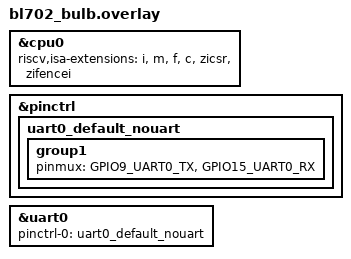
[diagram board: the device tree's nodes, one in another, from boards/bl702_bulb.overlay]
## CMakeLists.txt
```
cmake_minimum_required(VERSION 3.20.0)

find_package(Zephyr REQUIRED HINTS $ENV{ZEPHYR_BASE})

project(bl702_bulb)

get_filename_component(CHIP_ROOT ${ZEPHYR_BASE}/../modules/lib/matter REALPATH)

include(${CHIP_ROOT}/src/app/chip_data_model.cmake)

target_include_directories(app PRIVATE
    include
    ${CHIP_ROOT}/zzz_generated/app-common)

target_sources(app PRIVATE
    src/main.cpp
    src/ZclCallbacks.cpp
    src/LightDriver.cpp
    src/atomic_helpers.c)

# Generates and compiles the endpoint/cluster code
chip_configure_data_model(app ZAP_FILE ${CMAKE_CURRENT_SOURCE_DIR}/lighting-app.zap)

if(NOT DEFINED ZEPHYR_CONNECTEDHOMEIP_MODULE_DIR)
    message(FATAL_ERROR "Matter is not registered as a Zephyr module. Add it to your west manifest.")
endif()
set(CHIP_ROOT ${ZEPHYR_CONNECTEDHOMEIP_MODULE_DIR})

# ot-config re-lists zephyr_interface's INTERFACE_COMPILE_DEFINITIONS, including
# $<COMPILE_LANGUAGE:CXX> generator expressions. openthread/CMakeLists.txt uses
# ot-config's defines to build a plain custom target, where COMPILE_LANGUAGE is
# invalid. Strip it so LLVM/Clang builds configure cleanly.
if(CONFIG_OPENTHREAD AND TARGET ot-config AND TARGET zephyr_interface)
    get_target_property(OT_CONFIG_DEFS ot-config INTERFACE_COMPILE_DEFINITIONS)
    if(OT_CONFIG_DEFS)
        list(FILTER OT_CONFIG_DEFS EXCLUDE REGEX "TARGET_PROPERTY:zephyr_interface,INTERFACE_COMPILE_DEFINITIONS")
    else()
        set(OT_CONFIG_DEFS "")
    endif()
    get_target_property(ZEPHYR_INTERFACE_DEFS zephyr_interface INTERFACE_COMPILE_DEFINITIONS)
    if(ZEPHYR_INTERFACE_DEFS)
        list(FILTER ZEPHYR_INTERFACE_DEFS EXCLUDE REGEX "COMPILE_LANGUAGE:CXX")
    else()
        set(ZEPHYR_INTERFACE_DEFS "")
    endif()
    set_target_properties(ot-config PROPERTIES
        INTERFACE_COMPILE_DEFINITIONS "${OT_CONFIG_DEFS};${ZEPHYR_INTERFACE_DEFS}")
endif()

include(${CHIP_ROOT}/src/app/chip_data_model.cmake)

target_compile_options(app PRIVATE -Werror -Wno-error=format)
if(CMAKE_C_COMPILER_ID STREQUAL "GNU")
    target_compile_options(app PRIVATE -Werror -Wno-error=maybe-uninitialized)
endif()

if(NOT APP_TASK_IMPL_HEADER STREQUAL "")
    target_compile_definitions(app PRIVATE APP_TASK_IMPL_HEADER="${APP_TASK_IMPL_HEADER}")
endif()

zephyr_linker_sources(RAM_SECTIONS reloc.ld)
zephyr_code_relocate(FILES
  ${ZEPHYR_BASE}/subsys/net/ip/net_if.c
  ${ZEPHYR_BASE}/subsys/net/ip/connection.c
  ${ZEPHYR_BASE}/subsys/net/ip/net_context.c
  ${ZEPHYR_BASE}/modules/mbedtls/zephyr_init.c
  ${ZEPHYR_BASE}/subsys/settings/src/settings_nvs.c
  LOCATION RETRAM_BSS)
zephyr_code_relocate(FILES
  src/main.cpp
  LOCATION ITCM_BSS)
```

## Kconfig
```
menu "Zephyr"
source "Kconfig.zephyr"
endmenu

module = APP
module-str = APP
source "subsys/logging/Kconfig.template.log_config"

if NET_L2_OPENTHREAD
choice OPENTHREAD_DEVICE_TYPE
	default OPENTHREAD_FTD
endchoice
endif # NET_L2_OPENTHREAD
```

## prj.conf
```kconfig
# A lot of this is the *absolute minimum* possible to use matter, it was never intended to run
# on a device with that little RAM

CONFIG_NETWORKING=y
CONFIG_NET_L2_OPENTHREAD=y
CONFIG_OPENTHREAD_THREAD_VERSION_1_2=y
CONFIG_OPENTHREAD_SLAAC=y
CONFIG_OPENTHREAD_MANUAL_START=y
CONFIG_OPENTHREAD_DEFAULT_TX_POWER=13

# Logging
CONFIG_LOG=n
# CONFIG_LOG_MAX_LEVEL=3
# CONFIG_MATTER_LOG_LEVEL=1
# CONFIG_LOG_MODE_MINIMAL=y

# Use NVS as settings backend
CONFIG_NVS=y
CONFIG_NVS_LOOKUP_CACHE=y
CONFIG_NVS_LOOKUP_CACHE_SIZE=128
CONFIG_NVS_INIT_BAD_MEMORY_REGION=y

# Kernel options
CONFIG_MAIN_STACK_SIZE=4096
CONFIG_INIT_STACKS=y

# Control
CONFIG_LED=y
CONFIG_LED_PWM=y

# Safety
CONFIG_WATCHDOG=y
CONFIG_REBOOT=y

# BLE for provisioning
CONFIG_BT=y
CONFIG_BT_PERIPHERAL=y
CONFIG_BT_DEVICE_NAME="BL702 Bulb"
CONFIG_BT_GAP_AUTO_UPDATE_CONN_PARAMS=y
CONFIG_BT_GATT_DYNAMIC_DB=y
CONFIG_BT_DEVICE_NAME_DYNAMIC=y
CONFIG_BT_DEVICE_NAME_GATT_WRITABLE=n
CONFIG_BT_BUF_ACL_TX_COUNT=2
CONFIG_BT_BUF_EVT_RX_COUNT=4
CONFIG_BT_BUF_ACL_RX_SIZE=100
CONFIG_BT_BUF_ACL_TX_SIZE=100
CONFIG_BT_L2CAP_TX_MTU=100

# Matter
CONFIG_CHIP=y
CONFIG_CHIP_PROJECT_CONFIG="include/CHIPProjectConfig.h"
CONFIG_CHIP_DEVICE_PRODUCT_ID=32773
CONFIG_CHIP_ENABLE_PAIRING_AUTOSTART=y
CONFIG_CHIP_FACTORY_DATA=n
CONFIG_CHIP_CRYPTO_PSA=y
CONFIG_CHIP_BLE_ADVERTISING_DURATION=15
CONFIG_CHIP_MALLOC_SYS_HEAP=y
CONFIG_CHIP_DEVICE_PRODUCT_NAME="BL702 Bulb"
CONFIG_CHIP_DEVICE_VENDOR_NAME="Zephyr Community"
# It is a RGBW dimmable Lamp with 5 PWM channels
CONFIG_CHIP_DEVICE_TYPE=269
CONFIG_CHIP_DEVICE_SOFTWARE_VERSION_STRING="Yes, there is software"
CONFIG_CHIP_DEVICE_HARDWARE_VERSION_STRING="Yes, there is hardware"
CONFIG_CHIP_DEVICE_SOFTWARE_VERSION=1
CONFIG_CHIP_DEVICE_HARDWARE_VERSION=1
CONFIG_CHIP_EXAMPLE_DEVICE_INFO_PROVIDER=n

CONFIG_POSIX_AEP_CHOICE_NONE=y

# Don't starve BLE by starting thread after a factory reset
CONFIG_CHIP_FACTORY_RESET_ERASE_SETTINGS=y

CONFIG_NET_IF_MCAST_IPV6_ADDR_COUNT=8
CONFIG_NET_IF_UNICAST_IPV6_ADDR_COUNT=6
CONFIG_NET_PKT_RX_COUNT=6
CONFIG_NET_PKT_TX_COUNT=4
CONFIG_NET_BUF_RX_COUNT=16
CONFIG_NET_BUF_TX_COUNT=12

CONFIG_STD_CPP17=y
CONFIG_BT_HOST_CRYPTO=y
CONFIG_SYSTEM_WORKQUEUE_STACK_SIZE=1024
CONFIG_MAIN_STACK_SIZE=2944
# CONFIG_SHELL_STACK_SIZE=3072
CONFIG_OPENTHREAD_THREAD_STACK_SIZE=5120

CONFIG_THREAD_LOCAL_STORAGE=y
# CONFIG_ASSERT=y

CONFIG_SHELL=n
#CONFIG_SHELL_MINIMAL=y
CONFIG_CHIP_LIB_SHELL=n
CONFIG_OPENTHREAD_SHELL=n

CONFIG_MBEDTLS_PSA_KEY_SLOT_COUNT=32
CONFIG_MBEDTLS_ENTROPY_C=y
CONFIG_MBEDTLS_PSA_DRIVER_GET_ENTROPY=y
CONFIG_MBEDTLS_PSA_STATIC_KEY_SLOTS=n
CONFIG_MBEDTLS_SSL_IN_CONTENT_LEN=1560
CONFIG_MBEDTLS_SSL_OUT_CONTENT_LEN=1560
CONFIG_MBEDTLS_ENABLE_HEAP=n

# CONFIG_COMMON_LIBC_MALLOC=y
# CONFIG_COMMON_LIBC_MALLOC_ARENA_SIZE=16384

# Save ram
CONFIG_CHIP_OPENTHREAD_FTD=n
CONFIG_OPENTHREAD_MTD=y
CONFIG_CHIP_ENABLE_DNS_CLIENT=n
CONFIG_OPENTHREAD_DNS_CLIENT=n
CONFIG_OPENTHREAD_NUM_MESSAGE_BUFFERS=48
CONFIG_OPENTHREAD_MAX_CHILDREN=1
CONFIG_OPENTHREAD_MAX_IP_ADDR_PER_CHILD=4
CONFIG_OPENTHREAD_TMF_ADDRESS_CACHE_ENTRIES=0
CONFIG_MAX_EVENT_QUEUE_SIZE=40
CONFIG_BT_GATT_CACHING=n
CONFIG_BT_LONG_WQ=n
CONFIG_POSIX_THREAD_THREADS_MAX=1
CONFIG_MAX_PTHREAD_MUTEX_COUNT=1
CONFIG_MAX_PTHREAD_COND_COUNT=1
CONFIG_MAX_PTHREAD_BARRIER_COUNT=1
CONFIG_NET_TC_RX_COUNT=0

CONFIG_NET_IPV6_NBR_CACHE=n
CONFIG_NET_IPV6_ND=n
CONFIG_NET_IPV6_DAD=n
CONFIG_NET_IPV6_MLD=n

CONFIG_BFLB_SHIM_HEAP_SIZE=4096
CONFIG_HEAP_MEM_POOL_SIZE=6144
CONFIG_HEAP_MEM_POOL_IGNORE_MIN=y
CONFIG_CBPRINTF_FP_SUPPORT=n
CONFIG_PICOLIBC_IO_FLOAT=n

# Slightly dangerous but only a possible (rare) problem for setup
CONFIG_BT_TX_PROCESSOR_THREAD=n

CONFIG_IDLE_STACK_SIZE=320
```

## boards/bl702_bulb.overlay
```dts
// /delete-node/ &slot0_partition;
// /delete-node/ &storage_partition;
//
// &kh25v80 {
// 	partitions {
// 		ranges;
// 		#address-cells = <1>;
// 		#size-cells = <1>;
//
// 		slot0_partition: partition@2000 {
// 			compatible = "zephyr,mapped-partition";
// 			label = "image-0";
// 			reg = <0x00002000 (0x00200000 - 0x2000)>;
// 			read-only;
// 		};
//
// 		storage_partition: partition@200000 {
// 			compatible = "zephyr,mapped-partition";
// 			label = "storage";
// 			reg = <0x00200000 0x200000>;
// 		};
// 	};
// };
//
// &sram0_bt {
// 	reg = <0x0 DT_SIZE_K(128)>;
// 	ranges = <0x0 0x0 DT_SIZE_K(128)>;
// };

/* Remove A extension */
&cpu0 {
	riscv,isa-extensions = "i", "m", "f", "c", "zicsr", "zifencei";
};


&pinctrl {
	uart0_default_nouart: uart0_default_nouart {
		group1 {
			pinmux = <GPIO9_UART0_TX>,
				 <GPIO15_UART0_RX>;
		};
	};
};

&uart0 {
	pinctrl-0 = <&uart0_default_nouart>;
	pinctrl-names = "default";
};
```

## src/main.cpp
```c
/*
 * Copyright (c) 2022-2026 Project CHIP Authors
 *
 * SPDX-License-Identifier: Apache-2.0
 *
 * Adapted from examples/platform/telink/common/src/mainCommon.cpp and
 * AppTaskCommon.cpp. Removed: buttons, LEDs, PWM manager, factory data, OTA,
 * identify effects, power-on factory reset, the application thread.
 *
 */

#include "LightDriver.h"

#include <string.h>

#include <zephyr/kernel.h>
#include <zephyr/logging/log.h>
#include <zephyr/bluetooth/bluetooth.h>
#include <zephyr/drivers/watchdog.h>
#include <zephyr/drivers/hwinfo.h>
#include <zephyr/settings/settings.h>
#include <zephyr/sys/util.h>
#include <zephyr/sys/reboot.h>

#include <app-common/zap-generated/attributes/Accessors.h>
#include <app/clusters/network-commissioning/network-commissioning.h>
#include <app/server/Server.h>
#include <credentials/DeviceAttestationCredsProvider.h>
#include <credentials/examples/DeviceAttestationCredsExample.h>
#include <data-model-providers/codegen/Instance.h>
#include <lib/support/CHIPMem.h>
#include <platform/CHIPDeviceLayer.h>
#include <platform/OpenThread/GenericNetworkCommissioningThreadDriver.h>
#include <setup_payload/OnboardingCodesUtil.h>

#ifdef CONFIG_WATCHDOG
#define WDT_TIMEOUT_MS     10000
#define WDT_FEED_PERIOD_MS 1000
static const struct device *const wdt = DEVICE_DT_GET(DT_ALIAS(watchdog0));
#endif

#define STEP_MS		72
#define STEP_CNT	24
#define BR_SCALE(v)	(v / 4U)

LOG_MODULE_REGISTER(app, CONFIG_CHIP_APP_LOG_LEVEL);

/* Commission indicating */
static bool attached = false;
static bool commissioned = false;
static bool started = false;
static size_t step = 0;
const uint8_t pwm_curve[STEP_CNT] = {
	BR_SCALE(0), BR_SCALE(17), BR_SCALE(32), BR_SCALE(45), BR_SCALE(57),  BR_SCALE(68), BR_SCALE(77), BR_SCALE(85), BR_SCALE(91), BR_SCALE(95), BR_SCALE(98), BR_SCALE(100),
	BR_SCALE(100), BR_SCALE(98), BR_SCALE(95), BR_SCALE(91), BR_SCALE(85), BR_SCALE(77), BR_SCALE(68), BR_SCALE(57), BR_SCALE(45), BR_SCALE(32), BR_SCALE(17), BR_SCALE(0),
};

/* Factory reset counter */
#define BOOT_COUNT_KEY		"bulb/boots"
#define BOOT_COUNT_RESET	3
#define BOOT_COUNT_CLEAR_DELAY	K_SECONDS(5)

static struct k_work_delayable boot_count_work;

static void store_boot(uint8_t count)
{
	int rc = settings_save_one(BOOT_COUNT_KEY, &count, sizeof(count));

	if (rc != 0) {
		LOG_ERR("boot count save failed: %d", rc);
	}
}

static void boot_count_clear(struct k_work *work)
{
	ARG_UNUSED(work);
	store_boot(0);
}

static bool check_boot_count()
{
	uint8_t count = 0;

	/* Missing key or read error: start from 0. */
	if (settings_load_one(BOOT_COUNT_KEY, &count, sizeof(count)) < 0) {
		count = 0;
	}

	count++;
	if (count >= BOOT_COUNT_RESET) {
		store_boot(0);
		return true;
	}

	store_boot(count);
	k_work_init_delayable(&boot_count_work, boot_count_clear);
	k_work_schedule(&boot_count_work, BOOT_COUNT_CLEAR_DELAY);

	return false;
}

using namespace chip;
using namespace chip::app;
using namespace chip::DeviceLayer;

namespace {

/* Network Commissioning cluster on endpoint 0, backed by OpenThread. */
Clusters::NetworkCommissioning::InstanceAndDriver<NetworkCommissioning::GenericThreadDriver>
	sThreadNetworkDriver(0 /* endpointId */);

void ChipEventHandler(const ChipDeviceEvent *event, intptr_t)
{
	switch (event->Type) {
	case DeviceEventType::kCHIPoBLEAdvertisingChange:
		LOG_INF("BLE advertising %s, %u connection(s)",
			ConnectivityMgr().IsBLEAdvertisingEnabled() ? "on" : "off",
			ConnectivityMgr().NumBLEConnections());
		break;
	case DeviceEventType::kThreadStateChange:
		LOG_INF("Thread: provisioned %d, attached %d",
			ConnectivityMgr().IsThreadProvisioned(),
			ConnectivityMgr().IsThreadAttached());
			if (ConnectivityMgr().IsThreadAttached() == true) {
				attached = true;
			}
		break;
	case DeviceEventType::kCommissioningComplete:
		commissioned = true;
		LOG_INF("Commissioning complete");
		break;
	case DeviceEventType::kFailSafeTimerExpired:
		LOG_ERR("Commissioning fail-safe expired");
		break;
	case DeviceEventType::kCHIPoBLEConnectionClosed:
#if !CHIP_DEVICE_CONFIG_SUPPORTS_CONCURRENT_CONNECTION
		/*
		 * Non-concurrent commissioning: Matter shuts the BLE layer down
		 * after answering ConnectNetwork. Once the link is really closed,
		 * tell the network commissioning cluster it may start Thread.
		 */
		if (!ConnectivityMgr().GetBleLayer()->IsInitialized()) {
			ChipDeviceEvent opEvent;
			int rc = bt_disable();

			if (rc != 0) {
				LOG_ERR("bt_disable failed: %d", rc);
			}

			opEvent.Type = DeviceEventType::kOperationalNetworkStarted;
			LOG_INF("BLE closed, starting Thread");
			if (PlatformMgr().PostEvent(&opEvent) != CHIP_NO_ERROR) {
				LOG_ERR("Could not post network-started event");
			}
		}
#endif
		break;
	default:
		break;
	}
}

void RestoreLightState()
{
	using Protocols::InteractionModel::Status;

	bool on = false;
	DataModel::Nullable<uint8_t> level;
	Clusters::ColorControl::ColorModeEnum mode;

	if (Clusters::LevelControl::Attributes::CurrentLevel::Get(LIGHT_ENDPOINT_ID, level) ==
	    Status::Success && !level.IsNull()) {
		LightDriver::SetLevel(level.Value());
	}

	if (Clusters::OnOff::Attributes::OnOff::Get(LIGHT_ENDPOINT_ID, &on) == Status::Success) {
		LightDriver::SetOn(on);
	}

	if (Clusters::ColorControl::Attributes::ColorMode::Get(LIGHT_ENDPOINT_ID, &mode)
	    != Status::Success) {
		return;
	}

	switch (mode) {
	case Clusters::ColorControl::ColorModeEnum::kCurrentHueAndCurrentSaturation: {
		uint8_t hue = 0, sat = 0;

		Clusters::ColorControl::Attributes::CurrentHue::Get(LIGHT_ENDPOINT_ID, &hue);
		Clusters::ColorControl::Attributes::CurrentSaturation::Get(LIGHT_ENDPOINT_ID, &sat);
		LightDriver::SetColorHS(hue, sat);
		break;
	}
	case Clusters::ColorControl::ColorModeEnum::kCurrentXAndCurrentY: {
		uint16_t x = 0, y = 0;

		Clusters::ColorControl::Attributes::CurrentX::Get(LIGHT_ENDPOINT_ID, &x);
		Clusters::ColorControl::Attributes::CurrentY::Get(LIGHT_ENDPOINT_ID, &y);
		LightDriver::SetColorXY(x, y);
		break;
	}
	case Clusters::ColorControl::ColorModeEnum::kColorTemperatureMireds: {
		uint16_t mireds = 0;

		Clusters::ColorControl::Attributes::ColorTemperatureMireds::Get(LIGHT_ENDPOINT_ID, &mireds);
		LightDriver::SetColorTemperature(mireds);
		break;
	}
	default:
		break;
	}
}

/*
 * Runs on the Matter thread, so the heavy part of start-up uses the Matter
 * stack (not main's) and the Matter stack lock is already held.
 */
void InitServer(intptr_t)
{
	static CommonCaseDeviceServerInitParams initParams;

	CHIP_ERROR err = initParams.InitializeStaticResourcesBeforeServerInit();
	if (err != CHIP_NO_ERROR) {
		LOG_ERR("Server params init failed: %" CHIP_ERROR_FORMAT, err.Format());
		return;
	}

	initParams.dataModelProvider =
		CodegenDataModelProviderInstance(initParams.persistentStorageDelegate);

	err = Server::GetInstance().Init(initParams);
	if (err != CHIP_NO_ERROR) {
		LOG_ERR("Server init failed: %" CHIP_ERROR_FORMAT, err.Format());
		return;
	}

	if (Server::GetInstance().GetFabricTable().FabricCount() > 0) {
		commissioned = true;
	}

	/* QR code payload and manual pairing code, on the UART. */
	ConfigurationMgr().LogDeviceConfig();
	PrintOnboardingCodes(RendezvousInformationFlags(RendezvousInformationFlag::kBLE));

	RestoreLightState();

	started = true;

	if (check_boot_count()) {
		LOG_INF("Power-cycle pattern detected, factory reset");
		chip::Server::GetInstance().ScheduleFactoryReset();
	}

	LOG_INF("Matter server started");
}

/* Use the chip's hardware ID as the Matter serial number, saved once. */
int SetSerialFromHardwareId()
{
	uint8_t id[8];
	char serial[2 * sizeof(id) + 1];
	char current[ConfigurationManager::kMaxSerialNumberLength + 1] = {};

	ssize_t len = hwinfo_get_device_id(id, sizeof(id));
	if (len <= 0) {
		LOG_WRN("No hardware ID, keeping default serial number");
		return -ENOTSUP;
	}

	bin2hex(id, len, serial, sizeof(serial));

	if (GetDeviceInstanceInfoProvider()->GetSerialNumber(current, sizeof(current)) == CHIP_NO_ERROR &&
	    strcmp(current, serial) == 0) {
		return 0;
	}

	if (ConfigurationMgr().StoreSerialNumber(serial, strlen(serial)) != CHIP_NO_ERROR) {
		LOG_ERR("Could not store serial number");
		return -EIO;
	}

	return 0;
}

CHIP_ERROR InitMatter()
{
	ReturnErrorOnFailure(Platform::MemoryInit());
	ReturnErrorOnFailure(PlatformMgr().InitChipStack());

	(void)SetSerialFromHardwareId();

	/*
	 * Bring Bluetooth up before OpenThread starts. In non-concurrent mode
	 * Matter defers bt_enable() until advertising begins, which is after Thread has started
	 * when a dataset is already stored.
	 */
	if (!bt_is_ready()) {
		int rc = bt_enable(nullptr);

		if (rc != 0) {
			LOG_ERR("bt_enable failed: %d", rc);
			return CHIP_ERROR_INTERNAL;
		}
	}

	ReturnErrorOnFailure(ThreadStackMgr().InitThreadStack());
	/* Always-on end device, matching CONFIG_OPENTHREAD_MTD=y. */
	ReturnErrorOnFailure(ConnectivityMgr().SetThreadDeviceType(
		ConnectivityManager::kThreadDeviceType_MinimalEndDevice));
	ReturnErrorOnFailure(sThreadNetworkDriver.Init());

	/* Test attestation credentials, valid for vendor ID 0xFFF1 only. */
	Credentials::SetDeviceAttestationCredentialsProvider(
		Credentials::Examples::GetExampleDACProvider());

	ReturnErrorOnFailure(PlatformMgr().AddEventHandler(ChipEventHandler, 0));

	/* Creates the Matter thread; from here the event queue is drained. */
	ReturnErrorOnFailure(PlatformMgr().StartEventLoopTask());

	return PlatformMgr().ScheduleWork(InitServer, 0);
}

} /* namespace */

#ifdef CONFIG_WATCHDOG

static void wdt_feed_thread(void *, void *, void *)
{
	int wdt_channel_id;
	int ret;
	struct wdt_timeout_cfg wdt_config = {
		.window = { .min = 0, .max = WDT_TIMEOUT_MS },
		.callback = nullptr,
		.flags = WDT_FLAG_RESET_SOC,
	};

	if (!device_is_ready(wdt)) {
		/* Reboot currently hangs the CPU but if wdt is installed, the result is the same */
		sys_reboot(0);
	}

	wdt_channel_id = wdt_install_timeout(wdt, &wdt_config);
	if (wdt_channel_id < 0) {
		sys_reboot(0);
	}

	ret = wdt_setup(wdt, 0);
	if (ret < 0) {
		sys_reboot(0);
	}

	while (true) {
		wdt_feed(wdt, wdt_channel_id);
		k_msleep(WDT_FEED_PERIOD_MS);
	}
}

K_THREAD_DEFINE(wdt_feed_tid, 512, wdt_feed_thread, NULL, NULL, NULL,
		K_LOWEST_APPLICATION_THREAD_PRIO, 0, 0);

#endif

int main(void)
{
	if (LightDriver::Init() < 0) {
		LOG_ERR("Failed to initialize LEDs");
		sys_reboot(0);
	}

	CHIP_ERROR err = InitMatter();

	if (err != CHIP_NO_ERROR) {
		LOG_ERR("Matter init failed: %" CHIP_ERROR_FORMAT, err.Format());
		return -1;
	}

	while (!commissioned) {
		/* Breath animation when pairing */
		if (started && !commissioned) {
			if (!attached) {
				LightDriver::SetAll(100, 0, pwm_curve[step], 0, 0, 0);
			} else {
				LightDriver::SetAll(100, pwm_curve[step], 0, 0, 0, 0);
			}
			step++;
			if (step >= STEP_CNT) {
				step = 0;
			}
		}
		k_msleep(STEP_MS);
	}

	return 0;
}
```

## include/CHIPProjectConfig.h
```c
/*
 *    Copyright (c) 2020-2026 Project CHIP Authors
 *    All rights reserved.
 *
 *    Licensed under the Apache License, Version 2.0 (the "License");
 *    you may not use this file except in compliance with the License.
 *    You may obtain a copy of the License at
 *
 *        http://www.apache.org/licenses/LICENSE-2.0
 *
 *    Unless required by applicable law or agreed to in writing, software
 *    distributed under the License is distributed on an "AS IS" BASIS,
 *    WITHOUT WARRANTIES OR CONDITIONS OF ANY KIND, either express or implied.
 *    See the License for the specific language governing permissions and
 *    limitations under the License.
 */

#pragma once

#ifndef CHIP_DEVICE_CONFIG_USE_TEST_SETUP_PIN_CODE
#define CHIP_DEVICE_CONFIG_USE_TEST_SETUP_PIN_CODE 20202021
#endif

#ifndef CHIP_DEVICE_CONFIG_USE_TEST_SETUP_DISCRIMINATOR
#define CHIP_DEVICE_CONFIG_USE_TEST_SETUP_DISCRIMINATOR 0xF00
#endif

#define CHIP_DEVICE_CONFIG_CHIP_TASK_NAME "CHIP"
#define CHIP_DEVICE_CONFIG_CHIP_TASK_PRIORITY (K_PRIO_PREEMPT(10))
#define CHIP_DEVICE_CONFIG_CHIP_TASK_STACK_SIZE 6144

#define CHIP_CONFIG_SECURITY_TEST_MODE 0
#define CHIP_DEVICE_CONFIG_DEVICE_VENDOR_ID 0xFFF1
#define CHIP_DEVICE_CONFIG_ENABLE_CHIPOBLE 1
#define CHIP_DEVICE_CONFIG_TEST_SERIAL_NUMBER "TEST_SN"
#define CHIP_DEVICE_CONFIG_EVENT_LOGGING_UTC_TIMESTAMPS 1
#define CHIP_CONFIG_MRP_LOCAL_ACTIVE_RETRY_INTERVAL (2000_ms32)

#define CHIP_DEVICE_CONFIG_SUPPORTS_CONCURRENT_CONNECTION 0

#define CHIP_SYSTEM_PACKETBUFFER_FROM_CHIP_HEAP 1
#define CHIP_SYSTEM_PACKETBUFFER_FROM_CHIP_POOL 0
#define CHIP_SYSTEM_CONFIG_POOL_USE_HEAP 1
#define CHIP_SYSTEM_CONFIG_PACKETBUFFER_CAPACITY_MAX 1280
#define CHIP_SYSTEM_CONFIG_PACKETBUFFER_POOL_SIZE 0
/* This should be at least 5, we can't do that. */
#define CHIP_CONFIG_MAX_FABRICS 3
#define CHIP_SYSTEM_CONFIG_USE_ZEPHYR_SOCKET_EXTENSIONS 0
#define CHIP_CONFIG_MAX_GROUP_DATA_PEERS 8
#define CHIP_DEVICE_CONFIG_EVENT_LOGGING_CRIT_BUFFER_SIZE  (512)
#define CHIP_DEVICE_CONFIG_EVENT_LOGGING_INFO_BUFFER_SIZE  (256)
#define CHIP_DEVICE_CONFIG_EVENT_LOGGING_DEBUG_BUFFER_SIZE (128)
```

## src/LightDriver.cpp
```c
/* SPDX-License-Identifier: Apache-2.0 */

#include "LightDriver.h"

#include <zephyr/kernel.h>
#include <zephyr/logging/log.h>
#include <zephyr/drivers/led.h>

#include <algorithm>

LOG_MODULE_DECLARE(app, CONFIG_CHIP_APP_LOG_LEVEL);

namespace {

const struct device *const leds = DEVICE_DT_GET(DT_COMPAT_GET_ANY_STATUS_OKAY(pwm_leds));

#define SQUARED_LIGHT(v, s)						\
	(((v) < 0.5f || (s) < 0.0f) ? 0.0f :				\
	(std::clamp((v) * (s) * (s) / 10000.0f, 1.0f, 100.0f) + 0.5f))

#define WHITE_GAIN(v) ((v) * 0.08f)

/* Limits of the two white LEDs, in mireds (1 000 000 / kelvin). */
#define COLD_WHITE_MIREDS	153.0f /* 6500 K */
#define WARM_WHITE_MIREDS	370.0f /* 2700 K */

#define PRINT_F(v) (int)(v), (int)((v) * 1000.0f) % 1000

struct {
	bool on;
	/* All 0 to 100 */
	float scale;
	float r;
	float g;
	float b;
	float cw; /* Cold White */
	float ww; /* Warm White */
} State = { false, 0.0f, 0.0f, 0.0f, 0.0f, 0.0f, 0.0f, };

void apply()
{
	LOG_DBG("light: %s, %d.%03d", State.on ? "on" : "off", PRINT_F(State.scale));
	LOG_DBG("rgb = { %d.%03d, %d.%03d, %d.%03d }, cw = %d.%03d, ww = %d.%03d",
		PRINT_F(State.r), PRINT_F(State.g), PRINT_F(State.b),
		PRINT_F(State.cw), PRINT_F(State.ww));

	if (State.on) {
		led_set_brightness(leds, 0, SQUARED_LIGHT(State.r, State.scale));
		led_set_brightness(leds, 1, SQUARED_LIGHT(State.g, State.scale));
		led_set_brightness(leds, 2, SQUARED_LIGHT(State.b, State.scale));
		led_set_brightness(leds, 3, SQUARED_LIGHT(State.cw, State.scale));
		led_set_brightness(leds, 4, SQUARED_LIGHT(State.ww, State.scale));
	} else {
		led_set_brightness(leds, 0, 0);
		led_set_brightness(leds, 1, 0);
		led_set_brightness(leds, 2, 0);
		led_set_brightness(leds, 3, 0);
		led_set_brightness(leds, 4, 0);
	}
}

/* Extract white part to enable brighter compound colors */
void rgb_white()
{
	float white = State.r;

	if (State.g < white) {
		white = State.g;
	}
	if (State.b < white) {
		white = State.b;
	}

	if (white > 50.0f) {
		State.r -= white;
		State.g -= white;
		State.b -= white;
		State.cw = WHITE_GAIN(white) * 0.5f;
		State.ww = WHITE_GAIN(white) * 0.5f;
	} else {
		State.cw = 0.0f;
		State.ww = 0.0f;
	}
}

/* Scale so the strongest of r, g, b is 100; brightness comes from the level. */
void rgb_normalize()
{
	float max = State.r;

	if (State.g > max) {
		max = State.g;
	}
	if (State.b > max) {
		max = State.b;
	}
	if (max > 0.0f) {
		State.r = State.r * 100.0f / max;
		State.g = State.g * 100.0f / max;
		State.b = State.b * 100.0f / max;
	}
}

} /* namespace */

namespace LightDriver {

int Init()
{
	if (!device_is_ready(leds)) {
		return -ENODEV;
	}

	led_set_brightness(leds, 0, 0);
	led_set_brightness(leds, 1, 0);
	led_set_brightness(leds, 2, 0);
	led_set_brightness(leds, 3, 0);
	led_set_brightness(leds, 4, 0);

	return 0;
}

void SetOn(bool on)
{
	State.on = on;
	apply();
}

void SetAll(uint8_t scale, uint8_t r, uint8_t g, uint8_t b, uint8_t cw, uint8_t ww)
{
	State.scale = std::clamp((float)scale, 0.0f, 100.0f);
	if (scale > 0) {
		State.on = true;
	} else {
		State.on = false;
	}
	State.r = std::clamp((float)r, 0.0f, 100.0f);
	State.g = std::clamp((float)g, 0.0f, 100.0f);
	State.b = std::clamp((float)b, 0.0f, 100.0f);
	State.cw = std::clamp((float)cw, 0.0f, 100.0f);
	State.ww = std::clamp((float)ww, 0.0f, 100.0f);
	apply();
}

void SetLevel(uint8_t level)
{
	LOG_DBG("light: level %u", level);
	State.scale = (float)level * 100.0f / 254.0f;
	apply();
}

void SetColorXY(uint16_t x_in, uint16_t y_in)
{
	float x = (float)x_in / 65536.0f;
	float y = (float)y_in / 65536.0f;
	float X, Z;

	LOG_DBG("light: colour xy %u/%u", x_in, y_in);

	if (y < 0.0001f) {
		return;
	}

	/* CIE xy to XYZ with Y = 1. */
	X = x / y;
	Z = (1.0f - x - y) / y;

	/* XYZ to linear sRGB (D65). */
	State.r = std::max(324.04542f * X - 153.71385f - 49.85314f * Z, 0.0f);
	State.g = std::max(-96.92660f * X + 187.60108f + 4.15560f * Z, 0.0f);
	State.b = std::max(5.56434f * X - 20.40259f + 105.72252f * Z, 0.0f);

	rgb_normalize();
	rgb_white();
	apply();
}

void SetColorHS(uint8_t hue, uint8_t sat)
{
	float h = (float)hue * 6.0f / 254.0f; /* 0..6, one unit per 60 degrees */
	float s = (float)sat / 2.54f;
	int sector = (int)h;
	float f = h - (float)sector;
	float p = 100.0f - s;
	float q = 100.0f - s * f;
	float t = 100.0f - s * (1.0f - f);

	LOG_DBG("light: colour hue %u sat %u", hue, sat);

	switch (sector % 6) {
	case 0: State.r = 100.0f; State.g = t; State.b = p; break;
	case 1: State.r = q; State.g = 100.0f; State.b = p; break;
	case 2: State.r = p; State.g = 100.0f; State.b = t; break;
	case 3: State.r = p; State.g = q; State.b = 100.0f; break;
	case 4: State.r = t; State.g = p; State.b = 100.0f; break;
	default: State.r = 100.0f; State.g = p; State.b = q; break;
	}
	rgb_white();
	apply();
}

void SetColorTemperature(uint16_t mireds)
{
	float warm = std::clamp(((float)mireds - COLD_WHITE_MIREDS) /
			     (WARM_WHITE_MIREDS - COLD_WHITE_MIREDS), 0.0f, 1.0f);

	LOG_DBG("light: colour temperature %u mireds", mireds);

	State.ww = warm * 100.0f;
	State.cw = 100.0f - State.ww;
	State.r = 0;
	State.g = 0;
	State.b = 0;
	apply();
}

} /* namespace LightDriver */
```

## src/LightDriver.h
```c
/* SPDX-License-Identifier: Apache-2.0 */

#pragma once

#include <stdbool.h>
#include <stdint.h>

/* Endpoint that carries the light clusters in lighting-app.zap. */
#define LIGHT_ENDPOINT_ID 1

/*
 * Hardware boundary of the application. Everything Matter-side calls only
 * these functions; all of them are stubs that log and remember the value.
 * All calls arrive on the Matter thread.
 */
namespace LightDriver {

int Init();
void SetOn(bool on);
void SetAll(uint8_t scale, uint8_t r, uint8_t g, uint8_t b, uint8_t cw, uint8_t ww);
void SetLevel(uint8_t level);
void SetColorXY(uint16_t x, uint16_t y);
void SetColorHS(uint8_t hue, uint8_t sat);
void SetColorTemperature(uint16_t mireds);

} // namespace LightDriver
```

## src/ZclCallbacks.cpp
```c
/*
 * Copyright (c) 2021-2026 Project CHIP Authors
 *
 * SPDX-License-Identifier: Apache-2.0
 *
 * Adapted from examples/lighting-app/telink/src/ZclCallbacks.cpp.
 * The Telink version posts to an application thread; this one calls the
 * light driver directly, which saves that thread's stack and queue.
 *
 * LLM-generated
 */

#include "LightDriver.h"

#include <string.h>

#include <zephyr/logging/log.h>

#include <app-common/zap-generated/ids/Attributes.h>
#include <app-common/zap-generated/ids/Clusters.h>
#include <app/ConcreteAttributePath.h>

LOG_MODULE_DECLARE(app, CONFIG_CHIP_APP_LOG_LEVEL);

using namespace chip;
using namespace chip::app::Clusters;

static uint16_t ReadU16(const uint8_t *value)
{
	uint16_t v;

	memcpy(&v, value, sizeof(v));
	return v;
}

/* Called on the Matter thread after any attribute is written. */
void MatterPostAttributeChangeCallback(const chip::app::ConcreteAttributePath &attributePath,
				       uint8_t type, uint16_t size, uint8_t *value)
{
	static uint16_t sX, sY;
	static uint8_t sHue, sSat;

	const ClusterId clusterId = attributePath.mClusterId;
	const AttributeId attributeId = attributePath.mAttributeId;

	if (attributePath.mEndpointId != LIGHT_ENDPOINT_ID) {
		return;
	}

	if (clusterId == OnOff::Id && attributeId == OnOff::Attributes::OnOff::Id) {
		LightDriver::SetOn(*value != 0);
	} else if (clusterId == LevelControl::Id &&
		   attributeId == LevelControl::Attributes::CurrentLevel::Id) {
		LightDriver::SetLevel(*value);
	} else if (clusterId == ColorControl::Id) {
		switch (attributeId) {
		case ColorControl::Attributes::CurrentX::Id:
			sX = ReadU16(value);
			LightDriver::SetColorXY(sX, sY);
			break;
		case ColorControl::Attributes::CurrentY::Id:
			sY = ReadU16(value);
			LightDriver::SetColorXY(sX, sY);
			break;
		case ColorControl::Attributes::CurrentHue::Id:
			sHue = *value;
			LightDriver::SetColorHS(sHue, sSat);
			break;
		case ColorControl::Attributes::CurrentSaturation::Id:
			sSat = *value;
			LightDriver::SetColorHS(sHue, sSat);
			break;
		case ColorControl::Attributes::ColorTemperatureMireds::Id:
			LightDriver::SetColorTemperature(ReadU16(value));
			break;
		default:
			break;
		}
	}
}
```

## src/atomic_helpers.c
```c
/*
 * Copyright (c) 2026 The Zephyr Project Contributors
 *
 * SPDX-License-Identifier: Apache-2.0
 *
 * LLM-generated
 */

/*
 * Compiler atomic helpers (__atomic_*_N and __sync_*_N) implemented by
 * locking interrupts, for cores where the atomic instructions cannot be used.
 *
 * These are the functions GCC calls when the target has no 'A' extension in
 * -march, and the ones prebuilt libraries may reference by name. Valid on a
 * single core only.
 *
 * Handler's comment:
 * Reason on BL702: Atomics instructions are only supported in the TCM, while the blob requires the
 * A extension to be enabled. This combines needing the A extension, and needing it disabled, so
 * the solution is to disable it but provide the atomic functions needed by the blob,
 * here it's __atomic_fetch_add_4.
 */

#include <stdbool.h>
#include <stdint.h>
#include <string.h>

#include <zephyr/irq.h>

/*
 * The helper names are compiler built-ins, so each function is defined under
 * a private C name and given its real symbol name with an asm label.
 *
 * All of them are weak: Zephyr's lib/cpp cpp_atomics.c already provides some
 * (__atomic_compare_exchange_1/2/4), and those take precedence.
 */
#define SYM(name) __asm__(#name) __attribute__((weak))

#define ATOMIC_FETCH_OP(n, type, opname, expr)                                                     \
	type atomic_fetch_##opname##_##n(volatile void *ptr, type val, int memorder)               \
		SYM(__atomic_fetch_##opname##_##n);                                                \
	type atomic_fetch_##opname##_##n(volatile void *ptr, type val, int memorder)               \
	{                                                                                          \
		volatile type *p = ptr;                                                            \
		unsigned int key = irq_lock();                                                     \
		type old = *p;                                                                     \
												   \
		ARG_UNUSED(memorder);                                                              \
		*p = (type)(expr);                                                                 \
		irq_unlock(key);                                                                   \
		return old;                                                                        \
	}                                                                                          \
	type atomic_##opname##_fetch_##n(volatile void *ptr, type val, int memorder)               \
		SYM(__atomic_##opname##_fetch_##n);                                                \
	type atomic_##opname##_fetch_##n(volatile void *ptr, type val, int memorder)               \
	{                                                                                          \
		volatile type *p = ptr;                                                            \
		unsigned int key = irq_lock();                                                     \
		type old = *p;                                                                     \
		type new = (type)(expr);                                                           \
												   \
		ARG_UNUSED(memorder);                                                              \
		*p = new;                                                                          \
		irq_unlock(key);                                                                   \
		return new;                                                                        \
	}                                                                                          \
	type sync_fetch_and_##opname##_##n(volatile void *ptr, type val)                           \
		SYM(__sync_fetch_and_##opname##_##n);                                              \
	type sync_fetch_and_##opname##_##n(volatile void *ptr, type val)                           \
	{                                                                                          \
		return atomic_fetch_##opname##_##n(ptr, val, 0);                                   \
	}                                                                                          \
	type sync_##opname##_and_fetch_##n(volatile void *ptr, type val)                           \
		SYM(__sync_##opname##_and_fetch_##n);                                              \
	type sync_##opname##_and_fetch_##n(volatile void *ptr, type val)                           \
	{                                                                                          \
		return atomic_##opname##_fetch_##n(ptr, val, 0);                                   \
	}

#define ATOMIC_COMMON(n, type)                                                                     \
	ATOMIC_FETCH_OP(n, type, add, old + val)                                                   \
	ATOMIC_FETCH_OP(n, type, sub, old - val)                                                   \
	ATOMIC_FETCH_OP(n, type, and, old & val)                                                   \
	ATOMIC_FETCH_OP(n, type, or, old | val)                                                    \
	ATOMIC_FETCH_OP(n, type, xor, old ^ val)                                                   \
	ATOMIC_FETCH_OP(n, type, nand, ~(old & val))                                               \
												   \
	type atomic_exchange_##n(volatile void *ptr, type val, int memorder)                       \
		SYM(__atomic_exchange_##n);                                                        \
	type atomic_exchange_##n(volatile void *ptr, type val, int memorder)                       \
	{                                                                                          \
		volatile type *p = ptr;                                                            \
		unsigned int key = irq_lock();                                                     \
		type old = *p;                                                                     \
												   \
		ARG_UNUSED(memorder);                                                              \
		*p = val;                                                                          \
		irq_unlock(key);                                                                   \
		return old;                                                                        \
	}                                                                                          \
												   \
	bool atomic_compare_exchange_##n(volatile void *ptr, void *expected, type desired,         \
					 bool weak, int success, int failure)                      \
		SYM(__atomic_compare_exchange_##n);                                                \
	bool atomic_compare_exchange_##n(volatile void *ptr, void *expected, type desired,         \
					 bool weak, int success, int failure)                      \
	{                                                                                          \
		volatile type *p = ptr;                                                            \
		type exp;                                                                          \
		unsigned int key = irq_lock();                                                     \
		type old = *p;                                                                     \
		bool ok;                                                                           \
												   \
		ARG_UNUSED(weak);                                                                  \
		ARG_UNUSED(success);                                                               \
		ARG_UNUSED(failure);                                                               \
		memcpy(&exp, expected, sizeof(exp));                                               \
		ok = (old == exp);                                                                 \
		if (ok) {                                                                          \
			*p = desired;                                                              \
		} else {                                                                           \
			memcpy(expected, &old, sizeof(old));                                       \
		}                                                                                  \
		irq_unlock(key);                                                                   \
		return ok;                                                                         \
	}                                                                                          \
												   \
	type sync_val_compare_and_swap_##n(volatile void *ptr, type oldval, type newval)           \
		SYM(__sync_val_compare_and_swap_##n);                                              \
	type sync_val_compare_and_swap_##n(volatile void *ptr, type oldval, type newval)           \
	{                                                                                          \
		(void)atomic_compare_exchange_##n(ptr, &oldval, newval, false, 0, 0);              \
		return oldval;                                                                     \
	}                                                                                          \
												   \
	bool sync_bool_compare_and_swap_##n(volatile void *ptr, type oldval, type newval)          \
		SYM(__sync_bool_compare_and_swap_##n);                                             \
	bool sync_bool_compare_and_swap_##n(volatile void *ptr, type oldval, type newval)          \
	{                                                                                          \
		return atomic_compare_exchange_##n(ptr, &oldval, newval, false, 0, 0);             \
	}                                                                                          \
												   \
	type sync_lock_test_and_set_##n(volatile void *ptr, type val)                              \
		SYM(__sync_lock_test_and_set_##n);                                                 \
	type sync_lock_test_and_set_##n(volatile void *ptr, type val)                              \
	{                                                                                          \
		return atomic_exchange_##n(ptr, val, 0);                                           \
	}

ATOMIC_COMMON(1, uint8_t)
ATOMIC_COMMON(2, uint16_t)
ATOMIC_COMMON(4, uint32_t)
ATOMIC_COMMON(8, uint64_t)

/*
 * 64-bit loads and stores are two instructions on a 32-bit core, so the
 * compiler calls out for them even when the smaller sizes are inlined.
 */
uint64_t atomic_load_8(const volatile void *ptr, int memorder) SYM(__atomic_load_8);
uint64_t atomic_load_8(const volatile void *ptr, int memorder)
{
	const volatile uint64_t *p = ptr;
	unsigned int key = irq_lock();
	uint64_t val = *p;

	ARG_UNUSED(memorder);
	irq_unlock(key);
	return val;
}

void atomic_store_8(volatile void *ptr, uint64_t val, int memorder) SYM(__atomic_store_8);
void atomic_store_8(volatile void *ptr, uint64_t val, int memorder)
{
	volatile uint64_t *p = ptr;
	unsigned int key = irq_lock();

	ARG_UNUSED(memorder);
	*p = val;
	irq_unlock(key);
}
```
